# RP2040 register map
Vendor: Raspberry Pi; File version: 0.1
CPU: CM0PLUS r0p1, little endian, MPU, no FPU, VTOR, 2 interrupt priority bits, 26 interrupts
Registers are 32-bit, read-write, reset 0x0 unless marked. A register's access mark holds for its fields unless they carry their own. Offsets are from the block's base; [hi:lo] are bit positions; lines under a group give offsets from that group; {n}, {i} and the like mark numbered series; 'fields as' and 'values as' point back to an identical list.

## IO_BANK0
Base 0x40014000
{0x0+8i} GPIO[{i}] (i=0..29) group
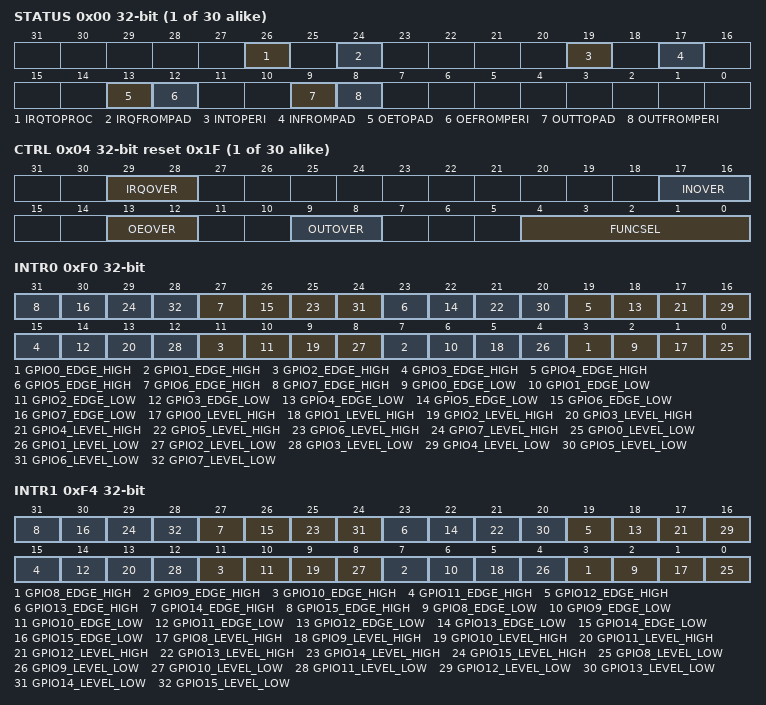
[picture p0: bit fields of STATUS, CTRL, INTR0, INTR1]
  0x00 STATUS ro — GPIO status
    [26] IRQTOPROC — interrupt to processors, after override is applied
    [24] IRQFROMPAD — interrupt from pad before override is applied
    [19] INTOPERI — input signal to peripheral, after override is applied
    [17] INFROMPAD — input signal from pad, before override is applied
    [13] OETOPAD — output enable to pad after register override is applied
    [12] OEFROMPERI — output enable from selected peripheral, before register override is applied
    [9] OUTTOPAD — output signal to pad after register override is applied
    [8] OUTFROMPERI — output signal from selected peripheral, before register override is applied
  0x04 CTRL reset 0x1F — GPIO control including function select and overrides.
    [29:28] IRQOVER
      0=NORMAL (don't invert the interrupt); 1=INVERT (invert the interrupt); 2=LOW (drive interrupt low); 3=HIGH (drive interrupt high)
    [17:16] INOVER
      0=NORMAL (don't invert the peri input); 1=INVERT (invert the peri input); 2=LOW (drive peri input low); 3=HIGH (drive peri input high)
    [13:12] OEOVER
      0=NORMAL (drive output enable from peripheral signal selected by funcsel); 1=INVERT (drive output enable from inverse of peripheral signal selected by funcsel); 2=DISABLE (disable output); 3=ENABLE (enable output)
    [9:8] OUTOVER
      0=NORMAL (drive output from peripheral signal selected by funcsel); 1=INVERT (drive output from inverse of peripheral signal selected by funcsel); 2=LOW (drive output low); 3=HIGH (drive output high)
    [4:0] FUNCSEL — 0-31 -> selects pin function according to the gpio table. 31 == NULL
      0=jtag; 1=spi; 2=uart; 3=i2c; 4=pwm; 5=sio; 6=pio0; 7=pio1; 8=clock; 9=usb; 31=null
0xF0 INTR0 access per field — Raw Interrupts
  [4n+3] GPIO{n}_EDGE_HIGH rw write-1-clears (n=0..7), [4n+2] GPIO{n}_EDGE_LOW rw write-1-clears (n=0..7), [4n+1] GPIO{n}_LEVEL_HIGH ro (n=0..7), [4n] GPIO{n}_LEVEL_LOW ro (n=0..7)
0xF4 INTR1 access per field — Raw Interrupts
  [4n-29] GPIO{n}_EDGE_HIGH rw write-1-clears (n=8..15), [4n-30] GPIO{n}_EDGE_LOW rw write-1-clears (n=8..15), [4n-31] GPIO{n}_LEVEL_HIGH ro (n=8..15), [4n-32] GPIO{n}_LEVEL_LOW ro (n=8..15)
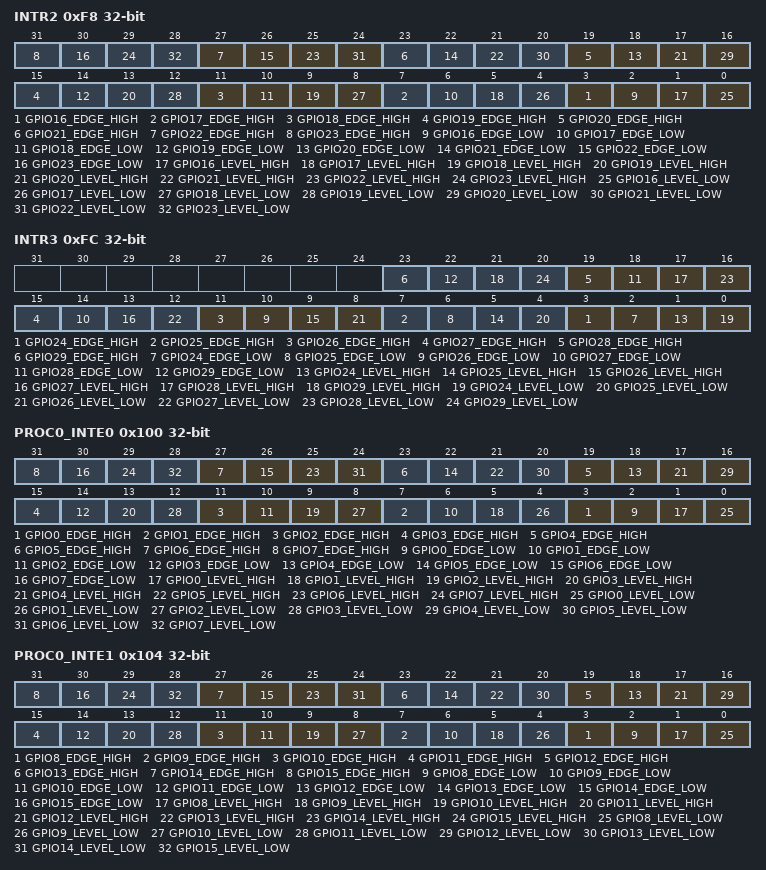
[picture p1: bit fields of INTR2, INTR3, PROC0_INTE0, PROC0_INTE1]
0xF8 INTR2 access per field — Raw Interrupts
  [4n-61] GPIO{n}_EDGE_HIGH rw write-1-clears (n=16..23), [4n-62] GPIO{n}_EDGE_LOW rw write-1-clears (n=16..23), [4n-63] GPIO{n}_LEVEL_HIGH ro (n=16..23), [4n-64] GPIO{n}_LEVEL_LOW ro (n=16..23)
0xFC INTR3 access per field — Raw Interrupts
  [4n-93] GPIO{n}_EDGE_HIGH rw write-1-clears (n=24..29), [4n-94] GPIO{n}_EDGE_LOW rw write-1-clears (n=24..29), [4n-95] GPIO{n}_LEVEL_HIGH ro (n=24..29), [4n-96] GPIO{n}_LEVEL_LOW ro (n=24..29)
0x100 PROC0_INTE0 — Interrupt Enable for proc0
  [4n+3] GPIO{n}_EDGE_HIGH (n=0..7), [4n+2] GPIO{n}_EDGE_LOW (n=0..7), [4n+1] GPIO{n}_LEVEL_HIGH (n=0..7), [4n] GPIO{n}_LEVEL_LOW (n=0..7)
0x104 PROC0_INTE1 — Interrupt Enable for proc0
  [4n-29] GPIO{n}_EDGE_HIGH (n=8..15), [4n-30] GPIO{n}_EDGE_LOW (n=8..15), [4n-31] GPIO{n}_LEVEL_HIGH (n=8..15), [4n-32] GPIO{n}_LEVEL_LOW (n=8..15)
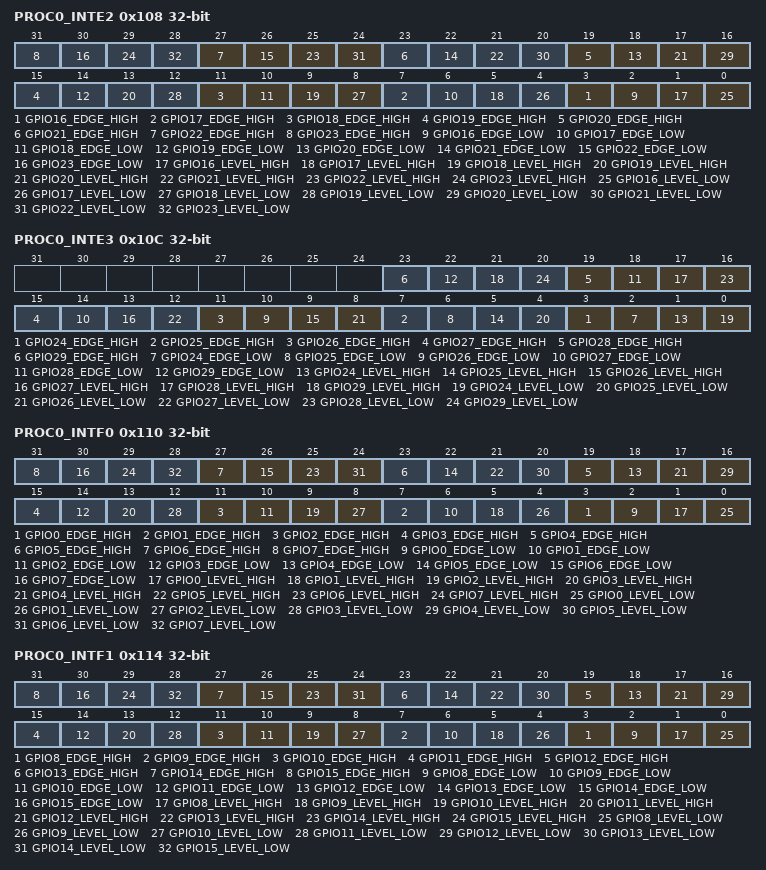
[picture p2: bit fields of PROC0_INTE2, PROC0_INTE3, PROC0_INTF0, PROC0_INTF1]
0x108 PROC0_INTE2 — Interrupt Enable for proc0
  [4n-61] GPIO{n}_EDGE_HIGH (n=16..23), [4n-62] GPIO{n}_EDGE_LOW (n=16..23), [4n-63] GPIO{n}_LEVEL_HIGH (n=16..23), [4n-64] GPIO{n}_LEVEL_LOW (n=16..23)
0x10C PROC0_INTE3 — Interrupt Enable for proc0
  [4n-93] GPIO{n}_EDGE_HIGH (n=24..29), [4n-94] GPIO{n}_EDGE_LOW (n=24..29), [4n-95] GPIO{n}_LEVEL_HIGH (n=24..29), [4n-96] GPIO{n}_LEVEL_LOW (n=24..29)
0x110 PROC0_INTF0 — Interrupt Force for proc0
  fields as PROC0_INTE0
0x114 PROC0_INTF1 — Interrupt Force for proc0
  fields as PROC0_INTE1
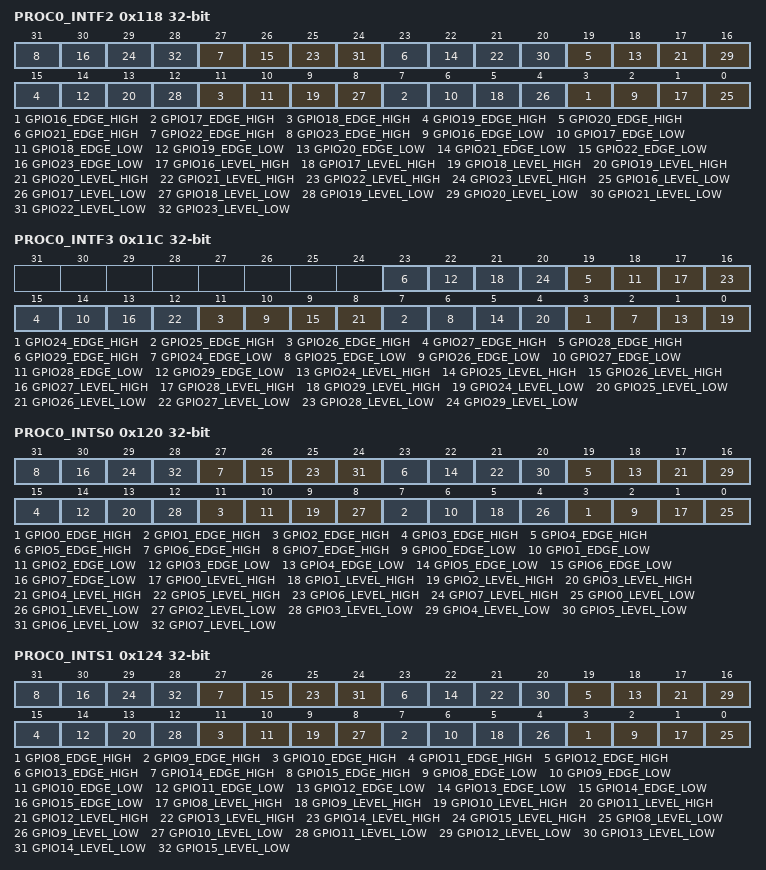
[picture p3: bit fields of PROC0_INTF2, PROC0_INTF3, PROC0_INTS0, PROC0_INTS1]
0x118 PROC0_INTF2 — Interrupt Force for proc0
  fields as PROC0_INTE2
0x11C PROC0_INTF3 — Interrupt Force for proc0
  fields as PROC0_INTE3
0x120 PROC0_INTS0 ro — Interrupt status after masking & forcing for proc0
  fields as PROC0_INTE0
0x124 PROC0_INTS1 ro — Interrupt status after masking & forcing for proc0
  fields as PROC0_INTE1
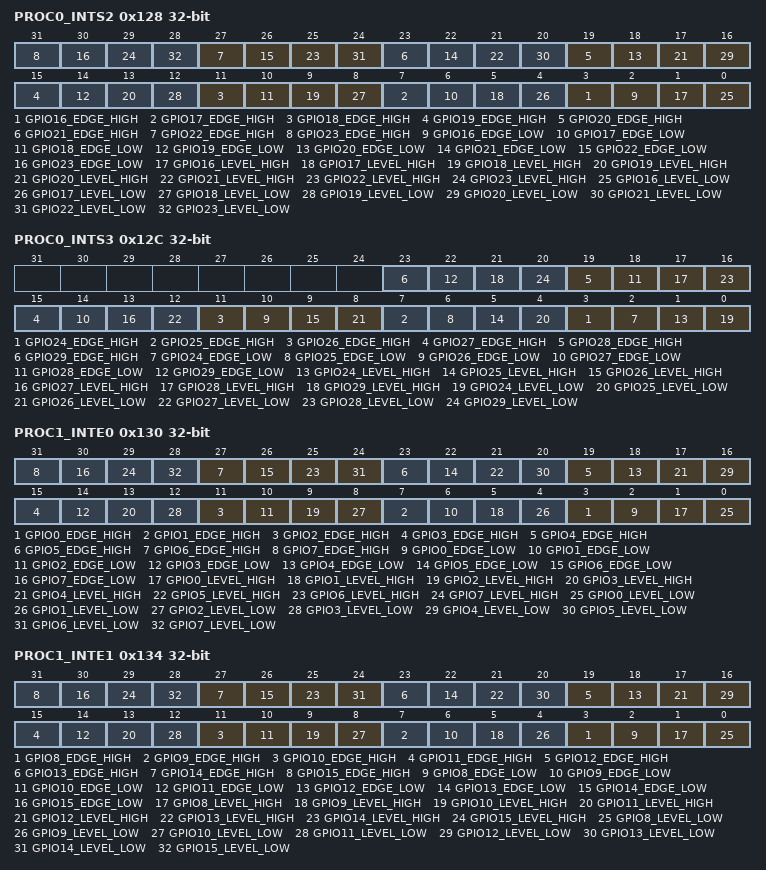
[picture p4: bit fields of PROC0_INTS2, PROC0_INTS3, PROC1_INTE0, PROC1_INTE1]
0x128 PROC0_INTS2 ro — Interrupt status after masking & forcing for proc0
  fields as PROC0_INTE2
0x12C PROC0_INTS3 ro — Interrupt status after masking & forcing for proc0
  fields as PROC0_INTE3
0x130 PROC1_INTE0 — Interrupt Enable for proc1
  fields as PROC0_INTE0
0x134 PROC1_INTE1 — Interrupt Enable for proc1
  fields as PROC0_INTE1
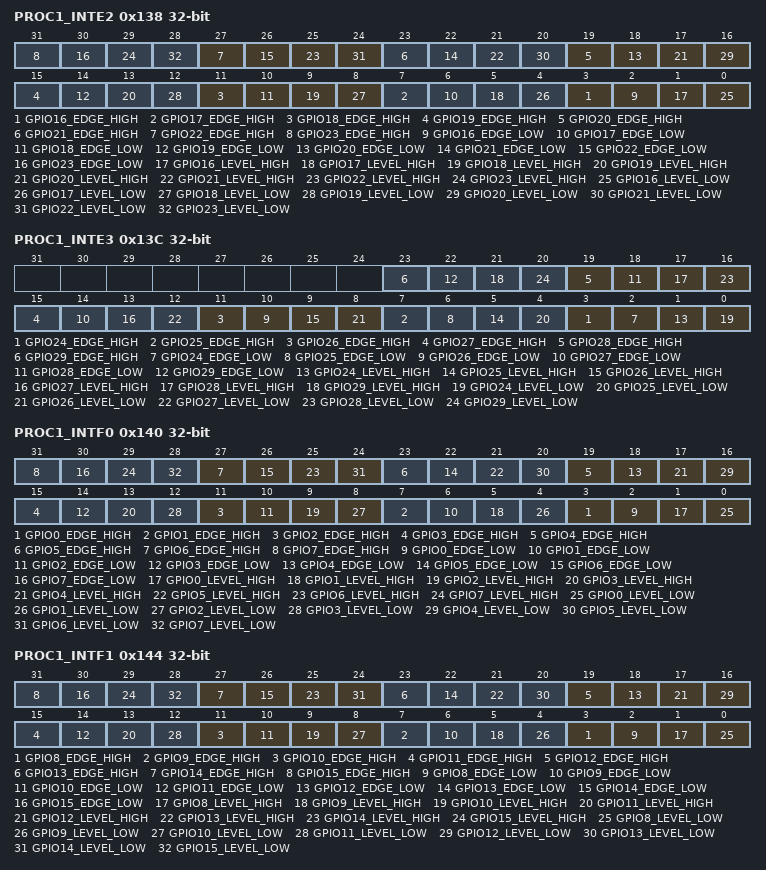
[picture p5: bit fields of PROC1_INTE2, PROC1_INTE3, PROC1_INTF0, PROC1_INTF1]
0x138 PROC1_INTE2 — Interrupt Enable for proc1
  fields as PROC0_INTE2
0x13C PROC1_INTE3 — Interrupt Enable for proc1
  fields as PROC0_INTE3
0x140 PROC1_INTF0 — Interrupt Force for proc1
  fields as PROC0_INTE0
0x144 PROC1_INTF1 — Interrupt Force for proc1
  fields as PROC0_INTE1
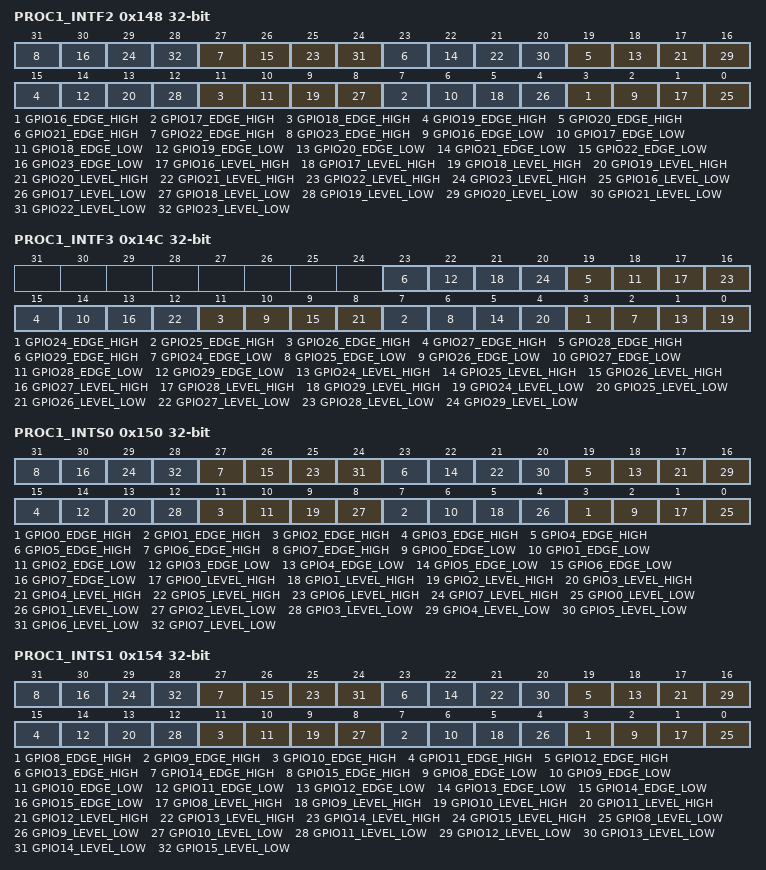
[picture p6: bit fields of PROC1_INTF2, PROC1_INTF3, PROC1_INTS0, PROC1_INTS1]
0x148 PROC1_INTF2 — Interrupt Force for proc1
  fields as PROC0_INTE2
0x14C PROC1_INTF3 — Interrupt Force for proc1
  fields as PROC0_INTE3
0x150 PROC1_INTS0 ro — Interrupt status after masking & forcing for proc1
  fields as PROC0_INTE0
0x154 PROC1_INTS1 ro — Interrupt status after masking & forcing for proc1
  fields as PROC0_INTE1
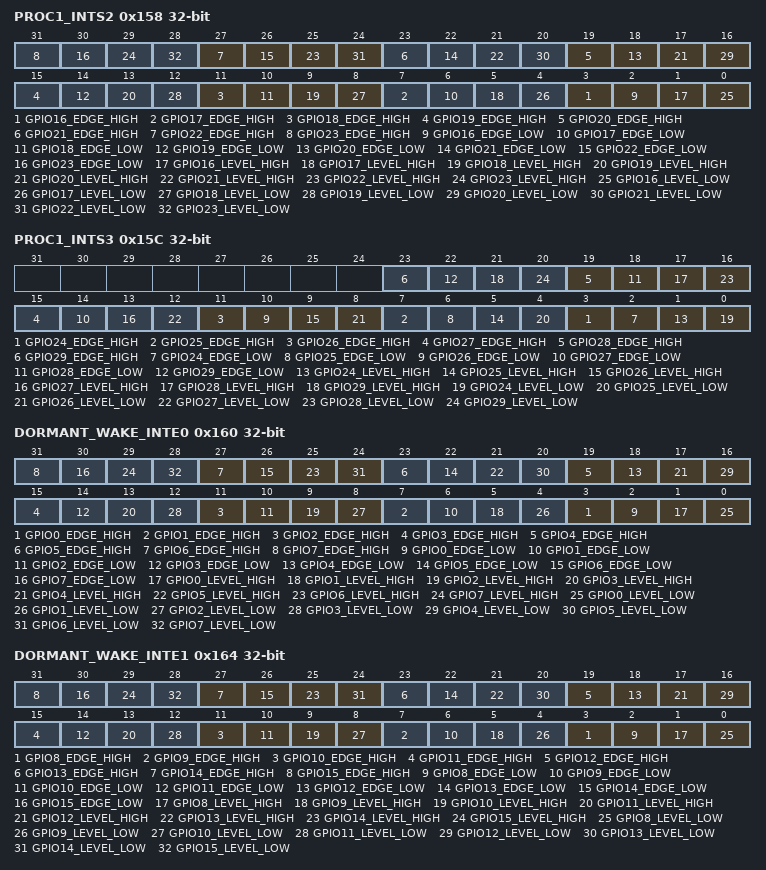
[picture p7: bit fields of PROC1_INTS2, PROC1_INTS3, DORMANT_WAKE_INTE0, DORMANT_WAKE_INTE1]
0x158 PROC1_INTS2 ro — Interrupt status after masking & forcing for proc1
  fields as PROC0_INTE2
0x15C PROC1_INTS3 ro — Interrupt status after masking & forcing for proc1
  fields as PROC0_INTE3
0x160 DORMANT_WAKE_INTE0 — Interrupt Enable for dormant_wake
  fields as PROC0_INTE0
0x164 DORMANT_WAKE_INTE1 — Interrupt Enable for dormant_wake
  fields as PROC0_INTE1
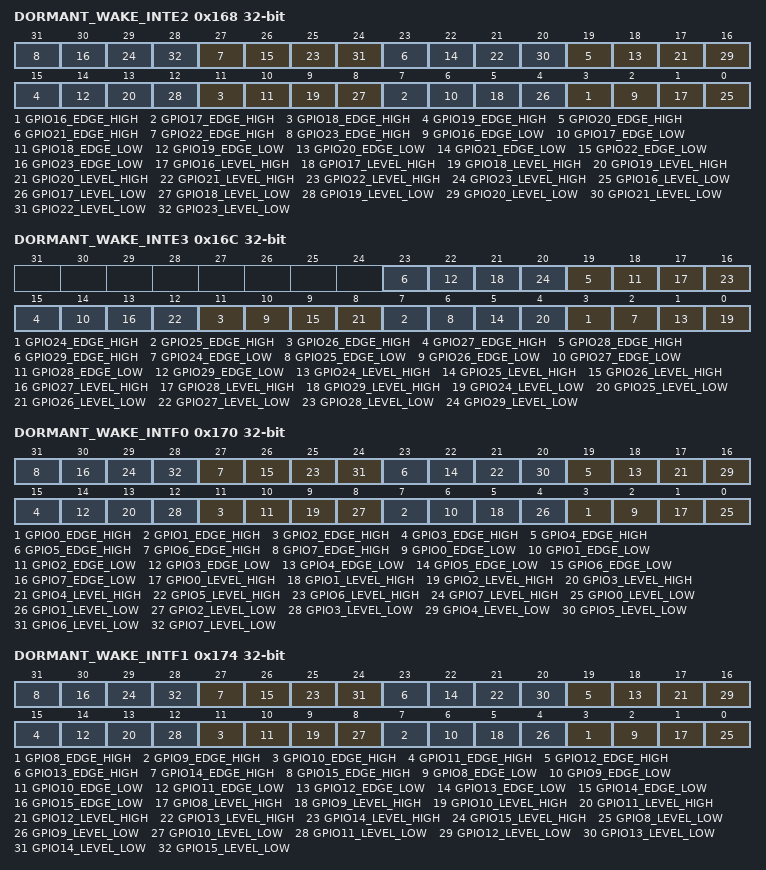
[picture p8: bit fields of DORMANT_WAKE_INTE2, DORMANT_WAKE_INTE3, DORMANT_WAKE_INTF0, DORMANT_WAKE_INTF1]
0x168 DORMANT_WAKE_INTE2 — Interrupt Enable for dormant_wake
  fields as PROC0_INTE2
0x16C DORMANT_WAKE_INTE3 — Interrupt Enable for dormant_wake
  fields as PROC0_INTE3
0x170 DORMANT_WAKE_INTF0 — Interrupt Force for dormant_wake
  fields as PROC0_INTE0
0x174 DORMANT_WAKE_INTF1 — Interrupt Force for dormant_wake
  fields as PROC0_INTE1
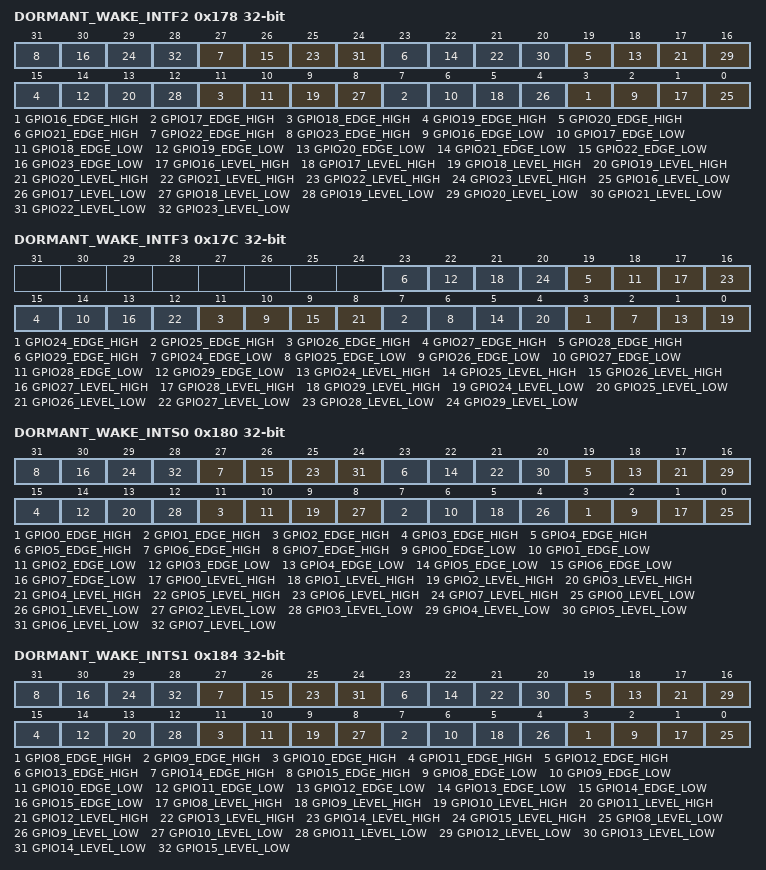
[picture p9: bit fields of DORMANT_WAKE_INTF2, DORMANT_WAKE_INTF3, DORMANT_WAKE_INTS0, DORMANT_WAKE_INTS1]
0x178 DORMANT_WAKE_INTF2 — Interrupt Force for dormant_wake
  fields as PROC0_INTE2
0x17C DORMANT_WAKE_INTF3 — Interrupt Force for dormant_wake
  fields as PROC0_INTE3
0x180 DORMANT_WAKE_INTS0 ro — Interrupt status after masking & forcing for dormant_wake
  fields as PROC0_INTE0
0x184 DORMANT_WAKE_INTS1 ro — Interrupt status after masking & forcing for dormant_wake
  fields as PROC0_INTE1
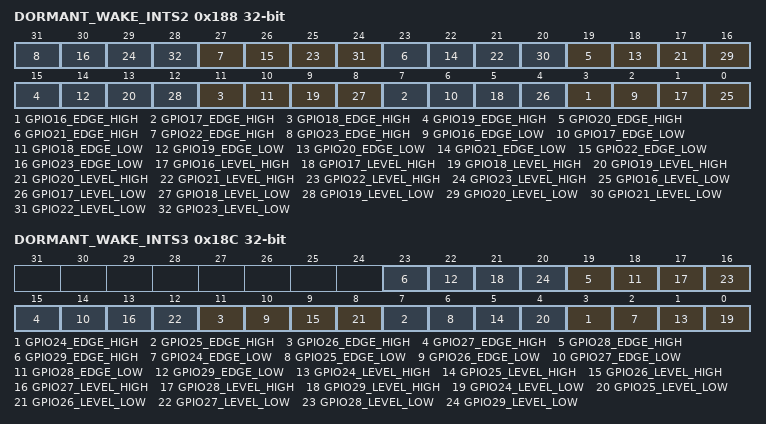
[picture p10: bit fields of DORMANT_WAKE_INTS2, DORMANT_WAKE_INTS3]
0x188 DORMANT_WAKE_INTS2 ro — Interrupt status after masking & forcing for dormant_wake
  fields as PROC0_INTE2
0x18C DORMANT_WAKE_INTS3 ro — Interrupt status after masking & forcing for dormant_wake
  fields as PROC0_INTE3
